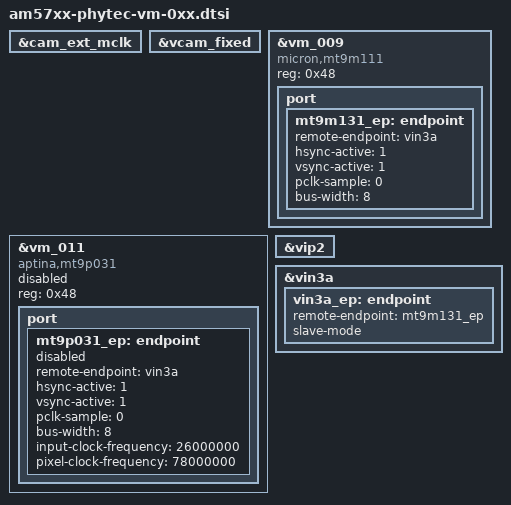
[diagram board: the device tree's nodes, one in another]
/*
 * Copyright (C) 2016 Russell Robinson <rrobinson@phytec.com>
 * Copyright (C) PHYTEC America, LLC.
 *
 * This program is free software; you can redistribute it and/or modify
 * it under the terms of the GNU General Public License version 2 as
 * published by the Free Software Foundation.
 */

/*
 * The board specific DTS file has to:
 *  - Specify camera reset and enable gpios
 *  - Mux the  enable pins
*/

&cam_ext_mclk {
	status = "okay";
};

&vcam_fixed {
	status = "okay";
};

&vm_009 {
	compatible = "micron,mt9m111";
	status = "okay";

	reg = <0x48>;

	port {
		mt9m131_ep: endpoint {
			status = "okay";
			remote-endpoint = <&vin3a>;

			hsync-active = <1>;
			vsync-active = <1>;
			pclk-sample = <0>;
			bus-width = <8>;
		};
	};

};

&vm_011 {
	compatible = "aptina,mt9p031";
	status = "disabled";

	reg = <0x48>;

	port {
		mt9p031_ep: endpoint {
			status = "disabled";
			remote-endpoint = <&vin3a>;

			hsync-active = <1>;
			vsync-active = <1>;
			pclk-sample = <0>;
			bus-width = <8>;
			input-clock-frequency = <26000000>;
			pixel-clock-frequency = <78000000>;
		};
	};
};

&vip2 {
	status = "okay";
};

&vin3a {
	status = "okay";

	vin3a_ep: endpoint {
		status = "okay";

		remote-endpoint = <&mt9m131_ep>;
		slave-mode;
	};
};
